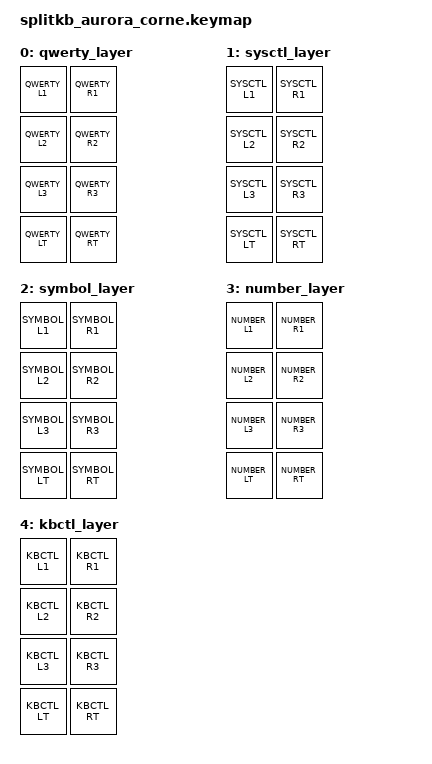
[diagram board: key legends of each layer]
#include <behaviors.dtsi>
#include <dt-bindings/zmk/keys.h>
#include <dt-bindings/zmk/bt.h>
#include <dt-bindings/zmk/outputs.h>
#include <dt-bindings/zmk/rgb.h>

#include "pvinis_keys.dtsi"
#include "pvinis_behaviors.dtsi"
#include "pvinis_split_layers.dtsi"

// The layers live in pvinis_split_layers.dtsi; this keymap is the reference layout.
// Drawing: keymap-drawer/splitkb_aurora_corne.svg

/ {
	conditional_layers {
		compatible = "zmk,conditional-layers";
		tri_layer {
			if-layers = <SYSCTL SYMBOL>;
			then-layer = <KBCTL>;
		};
	};

	keymap {
		compatible = "zmk,keymap";

		qwerty_layer {
			bindings = <
			QWERTY_L1  QWERTY_R1
			QWERTY_L2  QWERTY_R2
			QWERTY_L3  QWERTY_R3
			QWERTY_LT  QWERTY_RT
			>;
		};

		sysctl_layer {
			bindings = <
			SYSCTL_L1  SYSCTL_R1
			SYSCTL_L2  SYSCTL_R2
			SYSCTL_L3  SYSCTL_R3
			SYSCTL_LT  SYSCTL_RT
			>;
		};

		symbol_layer {
			bindings = <
			SYMBOL_L1  SYMBOL_R1
			SYMBOL_L2  SYMBOL_R2
			SYMBOL_L3  SYMBOL_R3
			SYMBOL_LT  SYMBOL_RT
			>;
		};

		number_layer {
			bindings = <
			NUMBER_L1  NUMBER_R1
			NUMBER_L2  NUMBER_R2
			NUMBER_L3  NUMBER_R3
			NUMBER_LT  NUMBER_RT
			>;
		};

		kbctl_layer {
			bindings = <
			KBCTL_L1  KBCTL_R1
			KBCTL_L2  KBCTL_R2
			KBCTL_L3  KBCTL_R3
			KBCTL_LT  KBCTL_RT
			>;
		};
	};
};


// TODO: home row mods
// TODO: if kbktl works, then move bt 1 2 reset there.
// TODO: game mode

// TODO: screenshot button
